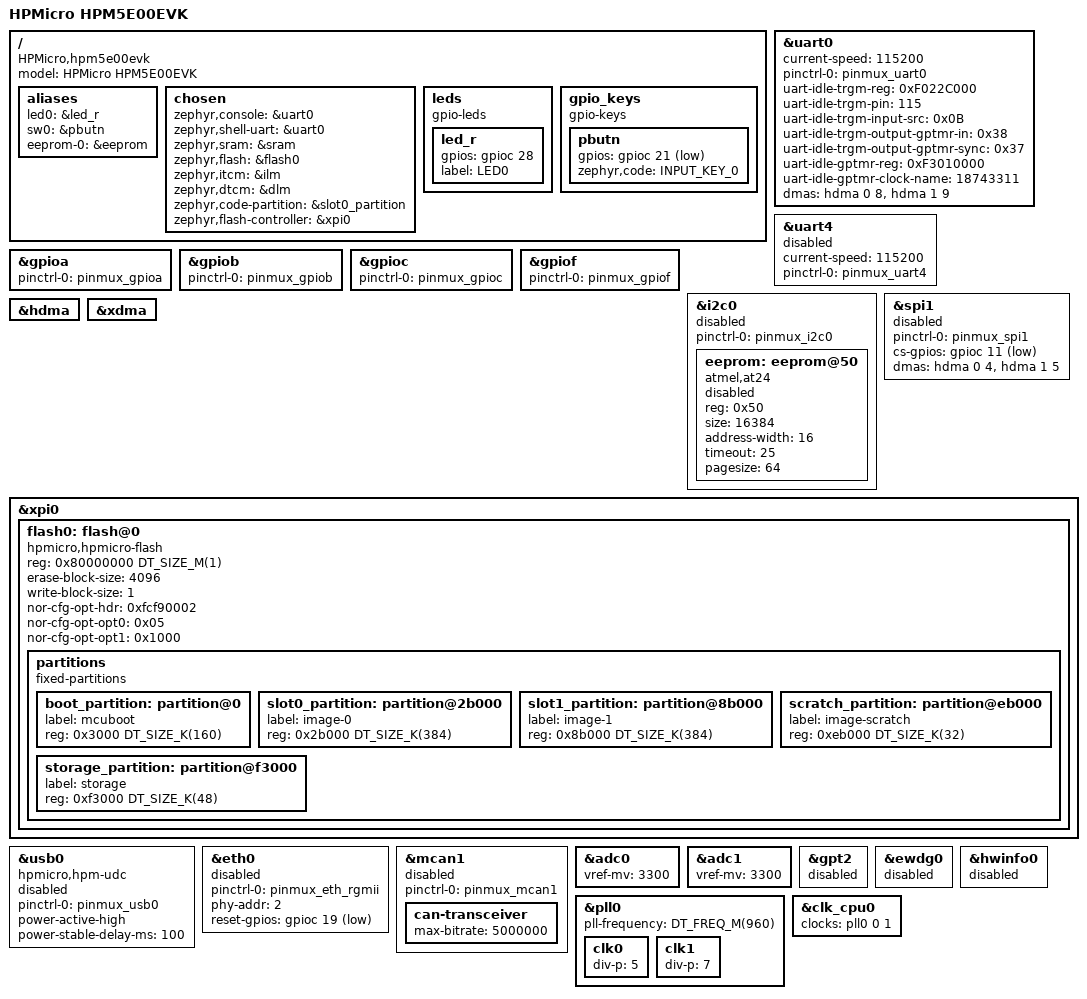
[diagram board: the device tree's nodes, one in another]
/dts-v1/;

/*
* Copyright (c) 2026 HPMicro
* SPDX-License-Identifier: Apache-2.0
*/

#include <hpmicro/HPM5E00/hpm5e31.dtsi>
#include "hpm5e00evk-pinctrl.dtsi"
#include <zephyr/dt-bindings/input/input-event-codes.h>

/ {
	model = "HPMicro HPM5E00EVK";
	compatible = "HPMicro,hpm5e00evk";
	aliases {
		led0 = &led_r;
		sw0 = &pbutn;
		eeprom-0 = &eeprom;
	};

	chosen {
		zephyr,console = &uart0;
		zephyr,shell-uart = &uart0;
		zephyr,sram = &sram;
		zephyr,flash = &flash0;
		zephyr,itcm = &ilm;
		zephyr,dtcm = &dlm;
		zephyr,code-partition = &slot0_partition;
		zephyr,flash-controller = &xpi0;
	};

	leds {
		compatible = "gpio-leds";
		led_r: led_r {
			gpios = <&gpioc 28 (GPIO_PULL_DOWN | GPIO_ACTIVE_HIGH)>;
			label = "LED0";
		};
	};

	gpio_keys {
		compatible = "gpio-keys";
		pbutn: pbutn {
			gpios = <&gpioc 21 (GPIO_PULL_UP | GPIO_ACTIVE_LOW)>;
			zephyr,code = <INPUT_KEY_0>;
		};
	};
};

&uart0 {
	status = "okay";
	current-speed = <115200>;
	pinctrl-0 = <&pinmux_uart0>;
	pinctrl-names = "default";
	uart-idle-trgm-reg = <0xF022C000>;
	uart-idle-trgm-pin = <115>;
	uart-idle-trgm-input-src = <0x0B>;
	uart-idle-trgm-output-gptmr-in = <0x38>;
	uart-idle-trgm-output-gptmr-sync = <0x37>;
	uart-idle-gptmr-reg = <0xF3010000>;
	uart-idle-gptmr-clock-name = <18743311>;
	dmas = <&hdma 0 8>, <&hdma 1 9>;
	dma-names = "rx", "tx";
};

&uart4 {
	status = "disabled";
	current-speed = <115200>;
	pinctrl-0 = <&pinmux_uart4>;
	pinctrl-names = "default";
};

&gpioa {
	pinctrl-0 = <&pinmux_gpioa>;
	pinctrl-names = "default";
	status = "okay";
};

&gpiob {
	pinctrl-0 = <&pinmux_gpiob>;
	pinctrl-names = "default";
	status = "okay";
};

&gpioc {
	pinctrl-0 = <&pinmux_gpioc>;
	pinctrl-names = "default";
	status = "okay";
};

&gpiof {
	pinctrl-0 = <&pinmux_gpiof>;
	pinctrl-names = "default";
	status = "okay";
};

&i2c0 {
	status = "disabled";
	pinctrl-0 = <&pinmux_i2c0>;
	pinctrl-names = "default";
	eeprom: eeprom@50 {
		compatible = "atmel,at24";
		status = "disabled";
		reg = <0x50>;
		size = <16384>;
		address-width = <16>;
		timeout = <25>;
		pagesize = <64>;
	};
};

&spi1 {
	status = "disabled";
	pinctrl-0 = <&pinmux_spi1>;
	pinctrl-names = "default";
	cs-gpios = <&gpioc 11 GPIO_ACTIVE_LOW>;
	/* HDMA channels 0 and 1, muxed to SPI1 RX and TX */
	dmas = <&hdma 0 4>, <&hdma 1 5>;
	dma-names = "rx", "tx";
};

&hdma {
	status = "okay";
};

&xdma {
	status = "okay";
};

&xpi0 {
	status = "okay";
	flash0: flash@0 {
		compatible = "hpmicro,hpmicro-flash", "soc-nv-flash";
		reg = <0x80000000 DT_SIZE_M(1)>;
		status = "okay";
		erase-block-size = <4096>;
		write-block-size = <1>;
		nor-cfg-opt-hdr = <0xfcf90002>;
		nor-cfg-opt-opt0 = <0x05>;
		nor-cfg-opt-opt1 = <0x1000>;
		partitions {
			compatible = "fixed-partitions";
			#address-cells = <1>;
			#size-cells = <1>;
			boot_partition: partition@0 {
				label = "mcuboot";
				reg = <0x3000 DT_SIZE_K(160)>;
			};

			slot0_partition: partition@2b000 {
				label = "image-0";
				reg = <0x2b000 DT_SIZE_K(384)>;
			};

			slot1_partition: partition@8b000 {
				label = "image-1";
				reg = <0x8b000 DT_SIZE_K(384)>;
			};

			scratch_partition: partition@eb000 {
				label = "image-scratch";
				reg = <0xeb000 DT_SIZE_K(32)>;
			};

			storage_partition: partition@f3000 {
				label = "storage";
				reg = <0xf3000 DT_SIZE_K(48)>;
			};
		};
	};
};

&usb0 {
	pinctrl-0 = <&pinmux_usb0>;
	pinctrl-names = "default";
};

zephyr_udc0: &usb0 {
	compatible = "hpmicro,hpm-udc";
	status = "disabled";
	power-active-high;
	power-stable-delay-ms = <100>;
};

&eth0 {
	pinctrl-0 = <&pinmux_eth_rgmii>;
	pinctrl-names = "default";
	phy-addr = <2>; /* rtl8211e */
		reset-gpios = <&gpioc 19 GPIO_ACTIVE_LOW>;
	status = "disabled";
};

&mcan1 {
	status = "disabled";
	pinctrl-0 = <&pinmux_mcan1>;
	pinctrl-names = "default";
	can-transceiver {
		max-bitrate = <5000000>;
	};
};

&adc0 {
	vref-mv = <3300>;
};

&adc1 {
	vref-mv = <3300>;
};

&gpt2 {
	status = "disabled";
};

&ewdg0 {
	status = "disabled";
};

&hwinfo0 {
	status = "disabled";
};

&pll0 {
	pll-frequency = <DT_FREQ_M(960)>;
	status = "okay";
	clk0 {
		div-p = <5>;
	};

	clk1 {
		div-p = <7>;
	};
};

&clk_cpu0 {
	clocks = <&pll0 0 1>;
	status = "okay";
};
